VERSION ""

NS_ :

BS_:

BU_:

BO_ 2 BPS_Trip: 1 Vector__XXX
	SG_ BPS_Trip : 0|1@1+ (1,0) [0|8031.875] "" Vector__XXX

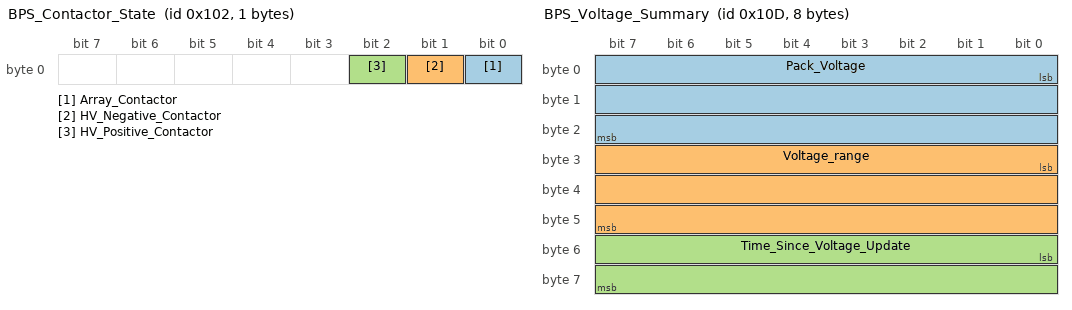
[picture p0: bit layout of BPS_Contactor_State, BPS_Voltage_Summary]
BO_ 258 BPS_Contactor_State: 1 Vector__XXX
	SG_ Array_Contactor : 0|1@1+ (0,0) [0|1] "" Vector__XXX
	SG_ HV_Negative_Contactor : 1|1@1+ (0,0) [0|1] "" Vector__XXX
	SG_ HV_Positive_Contactor : 2|1@1+ (0,0) [0|1] "" Vector__XXX

BO_ 268 Charging_Enable: 1 Vector__XXX
	SG_ Charge_Enable : 0|1@1+ (0,0) [0|1] "" Vector__XXX

BO_ 257 BPS_All_Clear: 1 Vector__XXX
	SG_ BPS_All_Clear : 0|1@1+ (0,0) [0|1] "" Vector__XXX

BO_ 263 WDog_Triggered: 1 Vector__XXX
	SG_ WDog_Triggered : 0|1@1+ (0,0) [0|1] "" Vector__XXX

BO_ 260 BPS_Voltage_Array: 5 Vector__XXX
	SG_ Voltage_Index : 0|8@1+ (0,0) [0|40] "" Vector__XXX
	SG_ Module_Voltage : 8|32@1+ (0,0) [0|1000000] "mV" Vector__XXX

BO_ 261 BPS_Temperature_Array: 5 Vector__XXX
	SG_ Temperature_Idx : 0|8@1+ (0,0) [0|40] "" Vector__XXX
	SG_ Module_Temperature : 8|32@1+ (0,0) [0|0] "C" Vector__XXX

BO_ 262 BPS_SOC: 4 Vector__XXX
	SG_ SOC : 0|32@1+ (0,0) [0|100] "%" Vector__XXX

BO_ 269 BPS_Voltage_Summary: 8 Vector__XXX
	SG_ Pack_Voltage : 0|24@1+ (0,0) [0|16777216] "mV" Vector__XXX
	SG_ Voltage_range : 24|24@1+ (0,0) [0|16777216] "mV" Vector__XXX
	SG_ Time_Since_Voltage_Update : 48|16@1+ (0,0) [0|65536] "ms" Vector__XXX

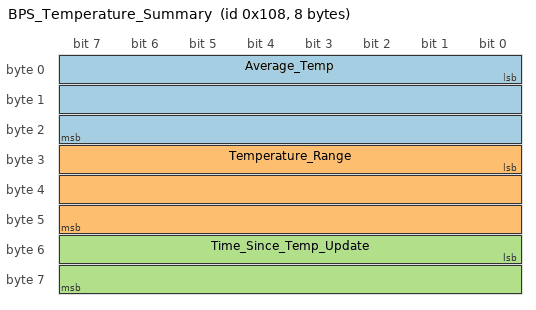
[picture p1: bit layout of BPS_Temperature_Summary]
BO_ 264 BPS_Temperature_Summary: 8 Vector__XXX
	SG_ Average_Temp : 0|24@1- (0,0) [0|0] "mC" Vector__XXX
	SG_ Temperature_Range : 24|24@1- (0,0) [0|0] "mC" Vector__XXX
	SG_ Time_Since_Temp_Update : 48|16@1+ (0,0) [0|0] "ms" Vector__XXX

BO_ 267 Supplemental_Voltage: 2 Vector__XXX
	SG_ Supplemental_Battery_Voltage : 0|16@1+ (0,0) [0|65535] "mV" Vector__XXX

BO_ 270 BPS_Fault_State: 1 Vector__XXX
	SG_ BPS_Fault_Status : 0|7@1+ (0,0) [0|1] "" Vector__XXX

CM_ BO_ 2 "1 indicates a BPS Fault, 0 indicates no BPS Fault";
CM_ SG_ 2 BPS_Trip "Indicates a BPS Fault";
CM_ BO_ 258 "BPS Contactor State";
CM_ SG_ 258 Array_Contactor "1 is on, 0 is off";
CM_ SG_ 258 HV_Negative_Contactor "1 is on, 0 is off";
CM_ SG_ 258 HV_Positive_Contactor "1 is on, 0 is off";
CM_ BO_ 268 "If BPS wants charging to enabled or disabled";
CM_ SG_ 268 Charge_Enable "1 is charging enabled, 0 is charging disabled";
CM_ BO_ 257 "Indicates if BPS is safe or not, sent only once";
CM_ SG_ 257 BPS_All_Clear "1 for everything running safe, 0 for not safe";
CM_ SG_ 263 WDog_Triggered "1 means watchdog triggered, 0 means watchdog not triggered";
CM_ BO_ 260 "Array of battery pack module voltages";
CM_ SG_ 260 Voltage_Index "Index of battery module";
CM_ BO_ 263 "Indicates if the BPS watchdog was tripped";
CM_ BO_ 261 "Array of battery pack temperatures";
CM_ BO_ 262 "State of Charge of the battery";
CM_ SG_ 262 SOC "State of Charge of battery";
CM_ BO_ 269 "uint24 pack voltage in mV, uint24 voltage range in mV, uint16 milliseconds since last voltage update: all little endian. 30 Hz";
CM_ SG_ 269 Pack_Voltage "Pack voltage in mV";
CM_ BO_ 264 "int24 average temp in millicelsius, int24 temp range in millicelsius, uint16 milliseconds since last temp update: all little endian 30 Hz";
CM_ BO_ 267 "Voltage of supplemental battery in mV";
CM_ BO_ 270 "What fault BPS is in";
BA_DEF_ SG_  "SPN" INT 0 524287;
BA_DEF_ BO_  "VFrameFormat" ENUM  "StandardCAN","ExtendedCAN","reserved","J1939PG";
BA_DEF_  "DatabaseVersion" STRING ;
BA_DEF_  "BusType" STRING ;
BA_DEF_  "ProtocolType" STRING ;
BA_DEF_  "DatabaseCompiler" STRING ;
BA_DEF_DEF_  "SPN" 0;
BA_DEF_DEF_  "VFrameFormat" "J1939PG";
BA_DEF_DEF_  "DatabaseVersion" "DEMO PLUS";
BA_DEF_DEF_  "BusType" "";
BA_DEF_DEF_  "ProtocolType" "";
BA_DEF_DEF_  "DatabaseCompiler" "";
BA_ "ProtocolType" "J1939";
BA_ "BusType" "CAN";
BA_ "DatabaseCompiler" "CSS ELECTRONICS (WWW.CSSELECTRONICS.COM)";
BA_ "DatabaseVersion" "1.0.0";
BA_ "SPN" SG_ 2364540158 EngineSpeed 190;
